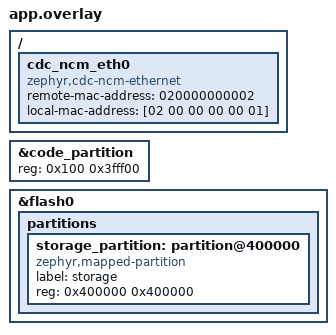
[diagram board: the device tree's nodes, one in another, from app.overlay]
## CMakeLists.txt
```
#pico-zephyr-project
#-------------------------------------------------------------------------------
# Zephyr Example Application
#
# Copyright (c) 2021 Nordic Semiconductor ASA
# SPDX-License-Identifier: Apache-2.0
#-------------------------------------------------------------------------------
# NOTE: Please do not remove the #pico-zephyr-project header, it is used by
# the Raspberry Pi Pico VS Code extension to identify the project type.
#-------------------------------------------------------------------------------

cmake_minimum_required(VERSION 3.20.0)

find_package(Zephyr REQUIRED HINTS $ENV{ZEPHYR_BASE})
project(pico_can_bridge LANGUAGES C)

target_sources(app PRIVATE
    src/can_bridge.c
    src/main.c
    src/http_server.c
    src/storage.c
    src/usb_descriptors.c
)
```

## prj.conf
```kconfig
# Logging
CONFIG_LOG=y
CONFIG_LOG_PRINTK=y
CONFIG_LOG_DEFAULT_LEVEL=3
CONFIG_USBD_LOG_LEVEL_INF=y
CONFIG_UDC_DRIVER_LOG_LEVEL_INF=y

# Board peripherals
CONFIG_GPIO=y
CONFIG_SPI=y
CONFIG_REBOOT=y
CONFIG_CAN=y
CONFIG_CAN_MCP2515=y
CONFIG_CAN_DEFAULT_BITRATE=500000
CONFIG_JSON_LIBRARY=y

# Experimental user storage. This branch mounts LittleFS lazily from HTTP
# handlers so boot and USB enumeration stay close to the stable firmware.
CONFIG_FLASH=y
CONFIG_FLASH_MAP=y
CONFIG_FILE_SYSTEM=y
CONFIG_FILE_SYSTEM_LITTLEFS=y
CONFIG_MAIN_STACK_SIZE=4096

# USB device stack next
CONFIG_USB_DEVICE_STACK_NEXT=y
CONFIG_CDC_ACM_SERIAL_INITIALIZE_AT_BOOT=n
CONFIG_USBD_CDC_NCM_LOG_LEVEL_INF=y

# Networking over USB CDC-NCM
CONFIG_NETWORKING=y
CONFIG_NET_L2_ETHERNET=y
CONFIG_NET_IPV4=y
CONFIG_NET_IPV4_AUTO=y
CONFIG_NET_ARP=y
CONFIG_NET_UDP=y
CONFIG_NET_TCP=y
CONFIG_NET_NATIVE=y
CONFIG_NET_MGMT=y
CONFIG_NET_MGMT_EVENT=y
CONFIG_NET_CONFIG_SETTINGS=n
CONFIG_NET_DHCPV4=n
CONFIG_NET_SOCKETS=y

# mDNS / DNS-SD
CONFIG_NET_HOSTNAME_ENABLE=y
CONFIG_NET_HOSTNAME_UNIQUE=n
CONFIG_NET_HOSTNAME="pico-can-bridge"
CONFIG_MDNS_RESPONDER=y
CONFIG_DNS_SD=y
CONFIG_MDNS_RESPONDER_DNS_SD=y
CONFIG_NET_IF_MCAST_IPV4_ADDR_COUNT=3

# Keep packet pools explicit for the RP2040's RAM budget.
CONFIG_ZVFS_POLL_MAX=9
CONFIG_NET_PKT_RX_COUNT=10
CONFIG_NET_PKT_TX_COUNT=10
CONFIG_NET_BUF_RX_COUNT=20
CONFIG_NET_BUF_TX_COUNT=20
CONFIG_NET_CONTEXT_NET_PKT_POOL=y
CONFIG_TEST_RANDOM_GENERATOR=y

CONFIG_SYSTEM_WORKQUEUE_STACK_SIZE=2048
```

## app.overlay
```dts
/*
 * USB CDC-NCM virtual Ethernet interface.
 *
 * The remote MAC is the address advertised for the host side of the link.
 */
/ {
	cdc_ncm_eth0: cdc_ncm_eth0 {
		compatible = "zephyr,cdc-ncm-ethernet";
		remote-mac-address = "020000000002";
		local-mac-address = [02 00 00 00 00 01];
	};
};

/*
 * Keep the last 4 MiB of the 8 MiB external flash for experimental LittleFS
 * user storage. The application stays in the first 4 MiB.
 */
&code_partition {
	reg = <0x100 0x3fff00>;
};

&flash0 {
	partitions {
		storage_partition: partition@400000 {
			compatible = "zephyr,mapped-partition";
			label = "storage";
			reg = <0x400000 0x400000>;
		};
	};
};
```

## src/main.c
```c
#include <zephyr/kernel.h>
#include <zephyr/logging/log.h>
#include <zephyr/drivers/gpio.h>
#include <zephyr/net/net_if.h>
#include <zephyr/net/net_ip.h>
#include <zephyr/net/net_mgmt.h>
#include <zephyr/usb/usbd.h>
#include <zephyr/usb/usbd_msg.h>
#include <zephyr/sys/reboot.h>

#include "can_bridge.h"

LOG_MODULE_REGISTER(main, CONFIG_LOG_DEFAULT_LEVEL);

#define LED0_NODE DT_ALIAS(led0)

enum status_led_mode {
	STATUS_LED_BLINK,
	STATUS_LED_SOLID,
	STATUS_LED_ERROR,
};

static const struct gpio_dt_spec led = GPIO_DT_SPEC_GET(LED0_NODE, gpios);
static atomic_t status_led_mode = ATOMIC_INIT(STATUS_LED_BLINK);
static atomic_t heartbeat_period_ms = ATOMIC_INIT(1000);
static atomic_t network_should_run;
static atomic_t network_is_up;
static atomic_t network_is_ready;
static atomic_t http_server_is_started;

struct usbd_context *usb_device_init(void);
int http_server_start(void);

static struct net_mgmt_event_callback ipv4_addr_cb;
static struct k_work_delayable usb_ncm_network_work;
static struct k_work_delayable usb_ncm_startup_watchdog_work;
static struct k_work http_server_start_work;

static void status_led_set_blink(int period_ms)
{
	atomic_set(&heartbeat_period_ms, period_ms);
	atomic_set(&status_led_mode, STATUS_LED_BLINK);
}

static void status_led_set_solid(void)
{
	atomic_set(&status_led_mode, STATUS_LED_SOLID);
}

static void status_led_set_error(void)
{
	atomic_set(&heartbeat_period_ms, 100);
	atomic_set(&status_led_mode, STATUS_LED_ERROR);
}

static void usb_ncm_network_work_handler(struct k_work *work)
{
	struct net_if *iface = net_if_get_default();
	bool should_run = atomic_get(&network_should_run) != 0;

	ARG_UNUSED(work);

	if (iface == NULL) {
		LOG_ERR("No default network interface");
		status_led_set_error();
		return;
	}

	if (should_run && !atomic_get(&network_is_up)) {
		net_if_up(iface);
		atomic_set(&network_is_up, 1);
		if (!atomic_get(&network_is_ready)) {
			LOG_INF("CDC-NCM waiting for IPv4 link-local autoconfiguration");
		}
		return;
	}

	if (!should_run && atomic_get(&network_is_up)) {
		net_if_down(iface);
		atomic_set(&network_is_up, 0);
		atomic_set(&network_is_ready, 0);
		status_led_set_blink(500);
		LOG_INF("CDC-NCM network interface down");
	}
}

static void set_usb_ncm_network_state(bool up)
{
	atomic_set(&network_should_run, up ? 1 : 0);

	if (up) {
		k_work_schedule(&usb_ncm_network_work, K_SECONDS(1));
	} else {
		(void)k_work_cancel_delayable(&usb_ncm_network_work);
		(void)k_work_cancel_delayable(&usb_ncm_startup_watchdog_work);
		k_work_schedule(&usb_ncm_network_work, K_NO_WAIT);
	}
}

static void usb_ncm_startup_watchdog_work_handler(struct k_work *work)
{
	ARG_UNUSED(work);

	if (!atomic_get(&network_should_run) || atomic_get(&network_is_ready)) {
		return;
	}

	LOG_ERR("CDC-NCM did not reach link-local state; rebooting for USB recovery");
	status_led_set_error();
	k_sleep(K_MSEC(250));
	sys_reboot(SYS_REBOOT_COLD);
}

static void http_server_start_work_handler(struct k_work *work)
{
	int ret;

	ARG_UNUSED(work);

	if (atomic_cas(&http_server_is_started, 0, 1) == false) {
		return;
	}

	ret = http_server_start();
	if (ret != 0) {
		LOG_ERR("HTTP server failed: %d", ret);
		atomic_set(&http_server_is_started, 0);
		status_led_set_error();
	}
}

static void usbd_msg_cb(struct usbd_context *const ctx,
			const struct usbd_msg *const msg)
{
	ARG_UNUSED(ctx);

	switch (msg->type) {
	case USBD_MSG_CONFIGURATION:
		LOG_INF("USBD message: %s", usbd_msg_type_string(msg->type));
		set_usb_ncm_network_state(true);
		k_work_reschedule(&usb_ncm_startup_watchdog_work, K_SECONDS(6));
		break;
	case USBD_MSG_STACK_ERROR:
	case USBD_MSG_UDC_ERROR:
		LOG_WRN("USBD message: %s", usbd_msg_type_string(msg->type));
		atomic_set(&network_is_ready, 0);
		status_led_set_blink(500);
		set_usb_ncm_network_state(false);
		break;
	case USBD_MSG_RESET:
	case USBD_MSG_SUSPEND:
	case USBD_MSG_VBUS_REMOVED:
		LOG_INF("USBD message: %s", usbd_msg_type_string(msg->type));
		atomic_set(&network_is_ready, 0);
		status_led_set_blink(500);
		set_usb_ncm_network_state(false);
		break;
	case USBD_MSG_RESUME:
	case USBD_MSG_VBUS_READY:
		LOG_INF("USBD message: %s", usbd_msg_type_string(msg->type));
		status_led_set_blink(500);
		set_usb_ncm_network_state(true);
		k_work_reschedule(&usb_ncm_startup_watchdog_work, K_SECONDS(6));
		break;
	default:
		LOG_DBG("USBD message: %s", usbd_msg_type_string(msg->type));
		break;
	}
}

static void heartbeat_thread(void)
{
	if (!gpio_is_ready_dt(&led)) {
		LOG_ERR("LED GPIO is not ready");
		return;
	}

	if (gpio_pin_configure_dt(&led, GPIO_OUTPUT_INACTIVE) < 0) {
		LOG_ERR("Failed to configure LED GPIO");
		return;
	}

	while (1) {
		switch (atomic_get(&status_led_mode)) {
		case STATUS_LED_SOLID:
			(void)gpio_pin_set_dt(&led, 1);
			k_sleep(K_SECONDS(1));
			break;
		case STATUS_LED_ERROR:
		case STATUS_LED_BLINK:
		default:
			(void)gpio_pin_toggle_dt(&led);
			k_sleep(K_MSEC(atomic_get(&heartbeat_period_ms)));
			break;
		}
	}
}

K_THREAD_DEFINE(heartbeat_tid, 512, heartbeat_thread, NULL, NULL, NULL,
		7, 0, 0);

static void ipv4_addr_handler(struct net_mgmt_event_callback *cb,
			      uint64_t mgmt_event,
			      struct net_if *iface)
{
	struct net_if_config *cfg = net_if_get_config(iface);

	ARG_UNUSED(cb);
	ARG_UNUSED(mgmt_event);

	if (cfg == NULL || cfg->ip.ipv4 == NULL) {
		return;
	}

	for (int i = 0; i < NET_IF_MAX_IPV4_ADDR; i++) {
		struct net_if_addr *ifaddr = &cfg->ip.ipv4->unicast[i].ipv4;
		char addr[NET_IPV4_ADDR_LEN];

		if (!ifaddr->is_used || ifaddr->addr_type != NET_ADDR_AUTOCONF) {
			continue;
		}

		LOG_INF("CDC-NCM link-local IPv4 address: %s",
			net_addr_ntop(AF_INET, &ifaddr->address.in_addr,
				      addr, sizeof(addr)));
		LOG_INF("mDNS hostname: %s.local", CONFIG_NET_HOSTNAME);
		LOG_INF("HTTP service: _http._tcp.local on port 80");

		atomic_set(&network_is_ready, 1);
		(void)k_work_cancel_delayable(&usb_ncm_startup_watchdog_work);
		status_led_set_solid();
		k_work_submit(&http_server_start_work);
	}
}

static void register_usb_ncm_network_callbacks(void)
{
	k_work_init_delayable(&usb_ncm_network_work, usb_ncm_network_work_handler);
	k_work_init_delayable(&usb_ncm_startup_watchdog_work,
			      usb_ncm_startup_watchdog_work_handler);
	k_work_init(&http_server_start_work, http_server_start_work_handler);

	net_mgmt_init_event_callback(&ipv4_addr_cb, ipv4_addr_handler,
				     NET_EVENT_IPV4_ADDR_ADD);
	net_mgmt_add_event_callback(&ipv4_addr_cb);
}

int main(void)
{
	struct usbd_context *usbd;
	int ret;

	printk("Pico CAN Bridge CDC-NCM firmware\n");
	LOG_INF("Booted on %s", CONFIG_BOARD_TARGET);

	usbd = usb_device_init();
	if (usbd == NULL) {
		LOG_ERR("USB init failed");
		status_led_set_error();
		return 0;
	}

	register_usb_ncm_network_callbacks();

	ret = usbd_msg_register_cb(usbd, usbd_msg_cb);
	if (ret != 0) {
		LOG_ERR("USB message callback registration failed: %d", ret);
		status_led_set_error();
		return 0;
	}

	ret = usbd_enable(usbd);
	if (ret != 0) {
		LOG_ERR("USB enable failed: %d", ret);
		status_led_set_error();
		return 0;
	}

	status_led_set_blink(500);
	LOG_INF("USB CDC-NCM enabled");

	ret = can_bridge_init();
	if (ret != 0) {
		LOG_WRN("CAN bridge init failed: %d", ret);
	}

	while (1) {
		k_sleep(K_SECONDS(10));
	}

	return 0;
}
```

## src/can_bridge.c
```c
#include "can_bridge.h"

#include <errno.h>
#include <stdbool.h>
#include <stdint.h>
#include <string.h>

#include <zephyr/data/json.h>
#include <zephyr/device.h>
#include <zephyr/devicetree.h>
#include <zephyr/drivers/can.h>
#include <zephyr/kernel.h>
#include <zephyr/logging/log.h>
#include <zephyr/sys/util.h>

LOG_MODULE_REGISTER(can_bridge, CONFIG_LOG_DEFAULT_LEVEL);

#define CAN_NODE DT_CHOSEN(zephyr_canbus)
#define CAN_TX_TIMEOUT K_MSEC(100)
#define CAN_WS_JSON_MAX 256
#define CAN_TX_QUEUE_LEN 8
#define CAN_RX_QUEUE_LEN 8
#define CAN_TX_STACK_SIZE 2048
#define CAN_TX_PRIORITY 8

enum can_json_field {
	CAN_JSON_TYPE,
	CAN_JSON_BUS,
	CAN_JSON_ID,
	CAN_JSON_EXT,
	CAN_JSON_RTR,
	CAN_JSON_DLC,
	CAN_JSON_DATA,
	CAN_JSON_BITRATE,
	CAN_JSON_MODE,
};

struct can_json_message {
	const char *type;
	int32_t bus;
	int32_t id;
	bool ext;
	bool rtr;
	int32_t dlc;
	int32_t data[CAN_MAX_DLC];
	size_t data_len;
	int32_t bitrate;
	const char *mode;
};

static const struct device *const can_dev = DEVICE_DT_GET(CAN_NODE);
static atomic_t can_ready;
static uint32_t current_bitrate = CONFIG_CAN_DEFAULT_BITRATE;
static can_mode_t current_mode = CAN_MODE_NORMAL;
K_MSGQ_DEFINE(can_tx_queue, sizeof(struct can_frame),
	      CAN_TX_QUEUE_LEN, sizeof(uint32_t));
K_MSGQ_DEFINE(can_rx_queue, sizeof(struct can_frame),
	      CAN_RX_QUEUE_LEN, sizeof(uint32_t));
static K_THREAD_STACK_DEFINE(can_tx_stack, CAN_TX_STACK_SIZE);
static struct k_thread can_tx_thread_data;
static K_MUTEX_DEFINE(can_lock);
static int can_rx_filter_id = -1;
static atomic_t can_rx_streaming;

static const struct json_obj_descr can_json_descr[] = {
	JSON_OBJ_DESCR_PRIM(struct can_json_message, type, JSON_TOK_STRING),
	JSON_OBJ_DESCR_PRIM(struct can_json_message, bus, JSON_TOK_NUMBER),
	JSON_OBJ_DESCR_PRIM(struct can_json_message, id, JSON_TOK_NUMBER),
	JSON_OBJ_DESCR_PRIM(struct can_json_message, ext, JSON_TOK_TRUE),
	JSON_OBJ_DESCR_PRIM(struct can_json_message, rtr, JSON_TOK_TRUE),
	JSON_OBJ_DESCR_PRIM(struct can_json_message, dlc, JSON_TOK_NUMBER),
	JSON_OBJ_DESCR_ARRAY(struct can_json_message, data, CAN_MAX_DLC,
			     data_len, JSON_TOK_NUMBER),
	JSON_OBJ_DESCR_PRIM(struct can_json_message, bitrate, JSON_TOK_NUMBER),
	JSON_OBJ_DESCR_PRIM(struct can_json_message, mode, JSON_TOK_STRING),
};

static int ws_reply(char *response, size_t response_len, const char *code,
		    const char *message, int err)
{
	return snprintk(response, response_len,
			"{\"type\":\"error\",\"ok\":false,\"code\":\"%s\","
			"\"err\":%d,\"message\":\"%s\"}",
			code, err, message);
}

static const char *can_state_name(enum can_state state)
{
	switch (state) {
	case CAN_STATE_ERROR_ACTIVE:
		return "error-active";
	case CAN_STATE_ERROR_WARNING:
		return "error-warning";
	case CAN_STATE_ERROR_PASSIVE:
		return "error-passive";
	case CAN_STATE_BUS_OFF:
		return "bus-off";
	case CAN_STATE_STOPPED:
		return "stopped";
	default:
		return "unknown";
	}
}

static const char *can_mode_name(can_mode_t mode)
{
	if ((mode & CAN_MODE_LOOPBACK) != 0) {
		return "loopback";
	}

	if ((mode & CAN_MODE_LISTENONLY) != 0) {
		return "listen-only";
	}

	return "normal";
}

static int can_mode_from_name(const char *name, can_mode_t *mode)
{
	if (name == NULL || strcmp(name, "normal") == 0) {
		*mode = CAN_MODE_NORMAL;
		return 0;
	}

	if (strcmp(name, "loopback") == 0) {
		*mode = CAN_MODE_LOOPBACK;
		return 0;
	}

	if (strcmp(name, "listen-only") == 0) {
		*mode = CAN_MODE_LISTENONLY;
		return 0;
	}

	return -EINVAL;
}

int can_bridge_format_status(char *response, size_t response_len)
{
	struct can_bus_err_cnt err_cnt = { 0 };
	enum can_state state = CAN_STATE_STOPPED;
	int ret;

	k_mutex_lock(&can_lock, K_FOREVER);
	ret = can_get_state(can_dev, &state, &err_cnt);
	k_mutex_unlock(&can_lock);
	if (ret < 0) {
		return ws_reply(response, response_len, "can_status_failed",
				"Could not read CAN controller status", ret);
	}

	return snprintk(response, response_len,
			"{\"type\":\"can.status\",\"ok\":true,\"bus\":0,"
			"\"ready\":%s,\"state\":\"%s\",\"bitrate\":%u,"
			"\"mode\":\"%s\",\"txErr\":%u,\"rxErr\":%u,"
			"\"txQueueUsed\":%u,\"txQueueFree\":%u,"
			"\"rxQueueUsed\":%u,\"rxQueueFree\":%u}",
			atomic_get(&can_ready) ? "true" : "false",
			can_state_name(state), current_bitrate,
			can_mode_name(current_mode), err_cnt.tx_err_cnt,
			err_cnt.rx_err_cnt,
			k_msgq_num_used_get(&can_tx_queue),
			k_msgq_num_free_get(&can_tx_queue),
			k_msgq_num_used_get(&can_rx_queue),
			k_msgq_num_free_get(&can_rx_queue));
}

static void can_rx_callback(const struct device *dev, struct can_frame *frame,
			    void *user_data)
{
	ARG_UNUSED(dev);
	ARG_UNUSED(user_data);

	if (!atomic_get(&can_rx_streaming)) {
		return;
	}

	if (k_msgq_put(&can_rx_queue, frame, K_NO_WAIT) != 0) {
		LOG_WRN("CAN RX software queue full");
	}
}

void can_bridge_set_rx_streaming(bool enabled)
{
	if (enabled) {
		k_msgq_purge(&can_rx_queue);
		atomic_set(&can_rx_streaming, 1);
		return;
	}

	atomic_clear(&can_rx_streaming);
	k_msgq_purge(&can_rx_queue);
}

static void can_tx_thread(void *p1, void *p2, void *p3)
{
	ARG_UNUSED(p1);
	ARG_UNUSED(p2);
	ARG_UNUSED(p3);

	while (1) {
		struct can_frame frame;
		int ret;

		k_msgq_get(&can_tx_queue, &frame, K_FOREVER);

		LOG_INF("CAN TX worker sending: id=%u ext=%d rtr=%d dlc=%d",
			frame.id, (frame.flags & CAN_FRAME_IDE) != 0,
			(frame.flags & CAN_FRAME_RTR) != 0, frame.dlc);

		k_mutex_lock(&can_lock, K_FOREVER);
		ret = can_send(can_dev, &frame, CAN_TX_TIMEOUT, NULL, NULL);
		k_mutex_unlock(&can_lock);
		if (ret < 0) {
			LOG_WRN("CAN TX failed: %d", ret);
			continue;
		}

		LOG_INF("CAN TX submitted");
	}
}

int can_bridge_init(void)
{
	int ret;

	if (!device_is_ready(can_dev)) {
		LOG_ERR("CAN device is not ready");
		return -ENODEV;
	}

	ret = can_set_mode(can_dev, current_mode);
	if (ret < 0) {
		LOG_ERR("CAN normal mode failed: %d", ret);
		return ret;
	}

	ret = can_start(can_dev);
	if (ret < 0 && ret != -EALREADY) {
		LOG_ERR("CAN start failed: %d", ret);
		return ret;
	}

	const struct can_filter catch_all = {
		.id = 0,
		.mask = 0,
		.flags = 0,
	};

	can_rx_filter_id = can_add_rx_filter(can_dev, can_rx_callback, NULL,
					     &catch_all);
	if (can_rx_filter_id < 0) {
		LOG_ERR("CAN RX filter failed: %d", can_rx_filter_id);
		return can_rx_filter_id;
	}

	atomic_set(&can_ready, 1);
	k_thread_create(&can_tx_thread_data, can_tx_stack,
			K_THREAD_STACK_SIZEOF(can_tx_stack),
			can_tx_thread, NULL, NULL, NULL,
			CAN_TX_PRIORITY, 0, K_NO_WAIT);
	LOG_INF("CAN bus ready in normal mode at %u bit/s",
		CONFIG_CAN_DEFAULT_BITRATE);
	return 0;
}

int can_bridge_format_next_rx(char *response, size_t response_len)
{
	struct can_frame frame;
	size_t offset = 0;
	int ret;

	ret = k_msgq_get(&can_rx_queue, &frame, K_NO_WAIT);
	if (ret != 0) {
		return -EAGAIN;
	}

	ret = snprintk(response, response_len,
		       "{\"type\":\"can.rx\",\"bus\":0,\"id\":%u,"
		       "\"ext\":%s,\"rtr\":%s,\"dlc\":%u,\"data\":[",
		       frame.id,
		       (frame.flags & CAN_FRAME_IDE) != 0 ? "true" : "false",
		       (frame.flags & CAN_FRAME_RTR) != 0 ? "true" : "false",
		       frame.dlc);
	if (ret < 0 || ret >= response_len) {
		return -ENOMEM;
	}

	offset = ret;
	for (uint8_t i = 0; i < frame.dlc; i++) {
		ret = snprintk(&response[offset], response_len - offset,
			       "%s%u", i == 0 ? "" : ",", frame.data[i]);
		if (ret < 0 || ret >= response_len - offset) {
			return -ENOMEM;
		}
		offset += ret;
	}

	ret = snprintk(&response[offset], response_len - offset,
		       "],\"ts\":%lld}",
		       (long long)k_ticks_to_us_floor64(k_uptime_ticks()));
	if (ret < 0 || ret >= response_len - offset) {
		return -ENOMEM;
	}

	return 0;
}

static int format_can_tx_response(const struct can_json_message *msg,
				  char *response, size_t response_len)
{
	size_t offset;
	int ret;

	ret = snprintk(response, response_len,
		       "{\"type\":\"can.tx\",\"ok\":true,\"bus\":%d,"
		       "\"id\":%d,\"ext\":%s,\"rtr\":%s,\"dlc\":%d,"
		       "\"data\":[",
		       msg->bus, msg->id, msg->ext ? "true" : "false",
		       msg->rtr ? "true" : "false", msg->dlc);
	if (ret < 0 || ret >= response_len) {
		return -ENOMEM;
	}

	offset = ret;
	for (size_t i = 0; i < msg->data_len; i++) {
		ret = snprintk(&response[offset], response_len - offset,
			       "%s%d", i == 0 ? "" : ",", msg->data[i]);
		if (ret < 0 || ret >= response_len - offset) {
			return -ENOMEM;
		}
		offset += ret;
	}

	ret = snprintk(&response[offset], response_len - offset,
		       "],\"queued\":true,\"ts\":%lld}",
		       (long long)k_ticks_to_us_floor64(k_uptime_ticks()));
	if (ret < 0 || ret >= response_len - offset) {
		return -ENOMEM;
	}

	return 0;
}

static int validate_can_json(const struct can_json_message *msg, int64_t fields,
			     char *response, size_t response_len)
{
	const int64_t required = BIT(CAN_JSON_BUS) | BIT(CAN_JSON_ID) |
				 BIT(CAN_JSON_DLC);
	bool has_data = (fields & BIT(CAN_JSON_DATA)) != 0;

	if ((fields & required) != required) {
		return ws_reply(response, response_len, "missing_field",
				"CAN JSON must include bus, id and dlc", -EINVAL);
	}

	if (msg->bus != 0) {
		return ws_reply(response, response_len, "unsupported_bus",
				"Only CAN bus 0 is available", -ENODEV);
	}

	if (msg->dlc < 0 || msg->dlc > CAN_MAX_DLC) {
		return ws_reply(response, response_len, "invalid_dlc",
				"CAN dlc must be between 0 and 8", -EINVAL);
	}

	if (msg->id < 0 ||
	    (!msg->ext && msg->id > CAN_STD_ID_MASK) ||
	    (msg->ext && msg->id > CAN_EXT_ID_MASK)) {
		return ws_reply(response, response_len, "invalid_id",
				"CAN id is outside the selected frame format",
				-EINVAL);
	}

	if (!msg->rtr && msg->dlc > 0 && !has_data) {
		return ws_reply(response, response_len, "missing_data",
				"Data frames with dlc > 0 must include data",
				-EINVAL);
	}

	if (!msg->rtr && msg->data_len != (size_t)msg->dlc) {
		return ws_reply(response, response_len, "data_length_mismatch",
				"data length must match dlc", -EINVAL);
	}

	if (msg->rtr && has_data && msg->data_len > 0) {
		return ws_reply(response, response_len, "rtr_has_data",
				"RTR frames must not include data bytes", -EINVAL);
	}

	for (size_t i = 0; i < msg->data_len; i++) {
		if (msg->data[i] < 0 || msg->data[i] > 0xff) {
			return ws_reply(response, response_len, "invalid_data",
					"CAN data bytes must be between 0 and 255",
					-EINVAL);
		}
	}

	return 0;
}

static int handle_can_config_set(const struct can_json_message *msg,
				 int64_t fields, char *response,
				 size_t response_len)
{
	uint32_t bitrate = current_bitrate;
	can_mode_t mode = current_mode;
	int ret;

	if ((fields & BIT(CAN_JSON_BITRATE)) != 0) {
		if (msg->bitrate <= 0) {
			return ws_reply(response, response_len, "invalid_bitrate",
					"CAN bitrate must be positive", -EINVAL);
		}

		bitrate = (uint32_t)msg->bitrate;
	}

	if ((fields & BIT(CAN_JSON_MODE)) != 0) {
		ret = can_mode_from_name(msg->mode, &mode);
		if (ret < 0) {
			return ws_reply(response, response_len, "invalid_mode",
					"CAN mode must be normal, loopback or listen-only",
					ret);
		}
	}

	atomic_clear(&can_ready);
	k_mutex_lock(&can_lock, K_FOREVER);

	ret = can_stop(can_dev);
	if (ret < 0 && ret != -EALREADY) {
		goto out;
	}

	ret = can_set_mode(can_dev, mode);
	if (ret < 0) {
		goto out;
	}

	ret = can_set_bitrate(can_dev, bitrate);
	if (ret < 0) {
		goto out;
	}

	ret = can_start(can_dev);
	if (ret < 0 && ret != -EALREADY) {
		goto out;
	}

	current_mode = mode;
	current_bitrate = bitrate;
	atomic_set(&can_ready, 1);

out:
	k_mutex_unlock(&can_lock);
	if (ret < 0) {
		int config_ret = ret;

		k_mutex_lock(&can_lock, K_FOREVER);
		ret = can_start(can_dev);
		if (ret == 0 || ret == -EALREADY) {
			atomic_set(&can_ready, 1);
		}
		k_mutex_unlock(&can_lock);
		return ws_reply(response, response_len, "can_config_failed",
				"Could not apply CAN configuration", config_ret);
	}

	LOG_INF("CAN config applied: bitrate=%u mode=%s",
		current_bitrate, can_mode_name(current_mode));
	return can_bridge_format_status(response, response_len);
}

int can_bridge_handle_ws_text(const uint8_t *payload, size_t payload_len,
			      char *response, size_t response_len)
{
	struct can_json_message msg = { 0 };
	struct can_frame frame = { 0 };
	char json[CAN_WS_JSON_MAX];
	int64_t fields;
	int ret;

	if (!atomic_get(&can_ready)) {
		return ws_reply(response, response_len, "can_not_ready",
				"CAN controller is not ready", -ENODEV);
	}

	if (payload_len >= sizeof(json)) {
		return ws_reply(response, response_len, "payload_too_large",
				"WebSocket JSON payload is too large", -EMSGSIZE);
	}

	memcpy(json, payload, payload_len);
	json[payload_len] = '\0';

	fields = json_obj_parse(json, payload_len, can_json_descr,
				ARRAY_SIZE(can_json_descr), &msg);
	if (fields < 0) {
		return ws_reply(response, response_len, "invalid_json",
				"Could not parse CAN JSON payload", (int)fields);
	}

	if ((fields & BIT(CAN_JSON_TYPE)) != 0) {
		if (strcmp(msg.type, "can.status") == 0 ||
		    strcmp(msg.type, "can.config.get") == 0) {
			return can_bridge_format_status(response, response_len);
		}

		if (strcmp(msg.type, "can.config.set") == 0) {
			return handle_can_config_set(&msg, fields, response,
						     response_len);
		}

		if (strcmp(msg.type, "can.tx") != 0) {
			return ws_reply(response, response_len, "unsupported_type",
					"Unsupported WebSocket message type",
					-ENOTSUP);
		}
	}

	ret = validate_can_json(&msg, fields, response, response_len);
	if (ret != 0) {
		return ret;
	}

	frame.id = (uint32_t)msg.id;
	frame.dlc = (uint8_t)msg.dlc;
	frame.flags = (msg.ext ? CAN_FRAME_IDE : 0) |
		      (msg.rtr ? CAN_FRAME_RTR : 0);

	for (size_t i = 0; i < msg.data_len; i++) {
		frame.data[i] = (uint8_t)msg.data[i];
	}

	LOG_INF("CAN TX request accepted: bus=%d id=%d ext=%d rtr=%d dlc=%d",
		msg.bus, msg.id, msg.ext, msg.rtr, msg.dlc);

	ret = k_msgq_put(&can_tx_queue, &frame, K_NO_WAIT);
	if (ret < 0) {
		LOG_WRN("CAN TX software queue full: %d", ret);
		(void)ws_reply(response, response_len, "can_tx_failed",
			       "CAN TX software queue is full", ret);
		return ret;
	}

	return format_can_tx_response(&msg, response, response_len);
}
```

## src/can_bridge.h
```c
#ifndef CAN_BRIDGE_H
#define CAN_BRIDGE_H

#include <stddef.h>
#include <stdbool.h>
#include <stdint.h>

int can_bridge_init(void);
int can_bridge_handle_ws_text(const uint8_t *payload, size_t payload_len,
			      char *response, size_t response_len);
int can_bridge_format_next_rx(char *response, size_t response_len);
int can_bridge_format_status(char *response, size_t response_len);
void can_bridge_set_rx_streaming(bool enabled);

#endif
```

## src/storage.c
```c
#include "storage.h"

#include <errno.h>
#include <stdbool.h>
#include <stdint.h>

#include <zephyr/fs/fs.h>
#include <zephyr/fs/littlefs.h>
#include <zephyr/kernel.h>
#include <zephyr/logging/log.h>
#include <zephyr/storage/flash_map.h>
#include <zephyr/sys/util.h>

LOG_MODULE_REGISTER(storage, CONFIG_LOG_DEFAULT_LEVEL);

#define STORAGE_PATH "/lfs"
#define USER_DIR_PATH STORAGE_PATH "/user"
#define USER_INDEX_PATH STORAGE_PATH "/user/index.html"
#define STORAGE_PARTITION storage_partition
#define STORAGE_IO_CHUNK 512

FS_LITTLEFS_DECLARE_DEFAULT_CONFIG(storage);

static struct fs_mount_t storage_mount = {
	.type = FS_LITTLEFS,
	.fs_data = &storage,
	.storage_dev = (void *)PARTITION_ID(STORAGE_PARTITION),
	.mnt_point = STORAGE_PATH,
};

static K_MUTEX_DEFINE(storage_lock);
static bool mount_attempted;
static bool mounted;
static int mount_ret = -ENODEV;
static unsigned long total_kib;
static unsigned long free_kib;

static void update_space_locked(void)
{
	struct fs_statvfs stat;
	int ret;

	total_kib = 0;
	free_kib = 0;

	if (!mounted) {
		return;
	}

	ret = fs_statvfs(STORAGE_PATH, &stat);
	if (ret < 0) {
		LOG_WRN("LittleFS statvfs failed: %d", ret);
		return;
	}

	total_kib = (unsigned long)((uint64_t)stat.f_frsize * stat.f_blocks / 1024U);
	free_kib = (unsigned long)((uint64_t)stat.f_frsize * stat.f_bfree / 1024U);
}

int storage_mount_once(void)
{
	int ret;

	k_mutex_lock(&storage_lock, K_FOREVER);
	if (mount_attempted) {
		ret = mount_ret;
		k_mutex_unlock(&storage_lock);
		return ret;
	}

	mount_attempted = true;
	ret = fs_mount(&storage_mount);
	mount_ret = ret;
	mounted = (ret == 0);

	if (ret == 0) {
		update_space_locked();
		LOG_INF("LittleFS mounted at %s: %lu KiB total, %lu KiB free",
			STORAGE_PATH, total_kib, free_kib);
	} else {
		LOG_WRN("LittleFS mount failed: %d", ret);
	}

	k_mutex_unlock(&storage_lock);
	return ret;
}

void storage_get_status(struct storage_status *status)
{
	k_mutex_lock(&storage_lock, K_FOREVER);
	update_space_locked();
	status->attempted = mount_attempted;
	status->mounted = mounted;
	status->mount_ret = mount_ret;
	status->total_kib = total_kib;
	status->free_kib = free_kib;
	k_mutex_unlock(&storage_lock);
}

int storage_format_status_json(char *response, size_t response_len)
{
	struct storage_status status;

	(void)storage_mount_once();
	storage_get_status(&status);

	return snprintk(response, response_len,
			"{\"type\":\"fs.status\",\"ok\":%s,"
			"\"attempted\":%s,\"mounted\":%s,"
			"\"mountRet\":%d,\"path\":\"%s\","
			"\"totalKiB\":%lu,\"freeKiB\":%lu}",
			status.mounted ? "true" : "false",
			status.attempted ? "true" : "false",
			status.mounted ? "true" : "false",
			status.mount_ret, STORAGE_PATH,
			status.total_kib, status.free_kib);
}

int storage_user_index_size(size_t *len)
{
	struct fs_dirent entry;
	int ret;

	if (len == NULL) {
		return -EINVAL;
	}

	ret = storage_mount_once();
	if (ret < 0) {
		return ret;
	}

	ret = fs_stat(USER_INDEX_PATH, &entry);
	if (ret < 0) {
		return ret;
	}

	if (entry.type != FS_DIR_ENTRY_FILE) {
		return -EISDIR;
	}

	*len = entry.size;
	return 0;
}

int storage_stream_user_index(storage_write_cb_t writer, void *ctx)
{
	struct fs_file_t file;
	uint8_t buf[STORAGE_IO_CHUNK];
	int ret;

	if (writer == NULL) {
		return -EINVAL;
	}

	ret = storage_mount_once();
	if (ret < 0) {
		return ret;
	}

	fs_file_t_init(&file);
	ret = fs_open(&file, USER_INDEX_PATH, FS_O_READ);
	if (ret < 0) {
		return ret;
	}

	while (1) {
		ssize_t read_len = fs_read(&file, buf, sizeof(buf));

		if (read_len < 0) {
			ret = (int)read_len;
			break;
		}

		if (read_len == 0) {
			ret = 0;
			break;
		}

		ret = writer(ctx, buf, (size_t)read_len);
		if (ret < 0) {
			break;
		}
	}

	(void)fs_close(&file);
	return ret;
}

int storage_write_user_index_stream(size_t len, storage_read_cb_t reader,
				    void *ctx)
{
	struct fs_file_t file;
	struct fs_dirent entry;
	uint8_t buf[STORAGE_IO_CHUNK];
	size_t remaining = len;
	int ret;

	if (reader == NULL) {
		return -EINVAL;
	}

	ret = storage_mount_once();
	if (ret < 0) {
		return ret;
	}

	ret = fs_stat(USER_DIR_PATH, &entry);
	if (ret == -ENOENT) {
		ret = fs_mkdir(USER_DIR_PATH);
		if (ret < 0) {
			return ret;
		}
	} else if (ret < 0) {
		return ret;
	} else if (entry.type != FS_DIR_ENTRY_DIR) {
		return -ENOTDIR;
	}

	fs_file_t_init(&file);
	ret = fs_open(&file, USER_INDEX_PATH,
		      FS_O_CREATE | FS_O_TRUNC | FS_O_WRITE);
	if (ret < 0) {
		return ret;
	}

	while (remaining > 0) {
		size_t requested = MIN(remaining, sizeof(buf));
		size_t read_len = 0;
		size_t written_total = 0;

		ret = reader(ctx, buf, requested, &read_len);
		if (ret < 0) {
			break;
		}

		if (read_len == 0 || read_len > requested) {
			ret = -EIO;
			break;
		}

		while (written_total < read_len) {
			ssize_t written = fs_write(&file,
						   &buf[written_total],
						   read_len - written_total);
			if (written < 0) {
				ret = (int)written;
				break;
			}

			if (written == 0) {
				ret = -EIO;
				break;
			}

			written_total += (size_t)written;
		}

		if (ret < 0) {
			break;
		}

		remaining -= read_len;
	}

	if (ret < 0) {
		(void)fs_close(&file);
		return ret;
	}

	ret = fs_sync(&file);
	(void)fs_close(&file);

	if (ret < 0) {
		return ret;
	}

	if (remaining != 0) {
		return -EIO;
	}

	k_mutex_lock(&storage_lock, K_FOREVER);
	update_space_locked();
	k_mutex_unlock(&storage_lock);

	LOG_INF("Wrote %u bytes to %s", (unsigned int)len, USER_INDEX_PATH);
	return 0;
}
```

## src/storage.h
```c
#ifndef STORAGE_H
#define STORAGE_H

#include <stdbool.h>
#include <stddef.h>
#include <stdint.h>

struct storage_status {
	bool attempted;
	bool mounted;
	int mount_ret;
	unsigned long total_kib;
	unsigned long free_kib;
};

typedef int (*storage_read_cb_t)(void *ctx, uint8_t *buf, size_t max_len,
				 size_t *len);
typedef int (*storage_write_cb_t)(void *ctx, const uint8_t *buf, size_t len);

int storage_mount_once(void);
void storage_get_status(struct storage_status *status);
int storage_format_status_json(char *response, size_t response_len);
int storage_user_index_size(size_t *len);
int storage_stream_user_index(storage_write_cb_t writer, void *ctx);
int storage_write_user_index_stream(size_t len, storage_read_cb_t reader,
				    void *ctx);

#endif
```

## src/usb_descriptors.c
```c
#include <zephyr/device.h>
#include <zephyr/usb/usbd.h>
#include <zephyr/usb/usb_ch9.h>

#include <zephyr/logging/log.h>
LOG_MODULE_REGISTER(usb_descriptors, CONFIG_LOG_DEFAULT_LEVEL);

#define USB_VID_ZEPHYR 0x2FE3
#define USB_PID_PICO_CAN_BRIDGE 0x0100

USBD_DEVICE_DEFINE(pico_can_bridge_usbd,
		   DEVICE_DT_GET(DT_NODELABEL(zephyr_udc0)),
		   USB_VID_ZEPHYR, USB_PID_PICO_CAN_BRIDGE);

USBD_DESC_LANG_DEFINE(lang_desc);
USBD_DESC_MANUFACTURER_DEFINE(mfr_desc, "pico-can-bridge");
USBD_DESC_PRODUCT_DEFINE(product_desc, "Pico CAN Bridge CDC-NCM");
USBD_DESC_SERIAL_NUMBER_DEFINE(serial_desc);

USBD_DESC_CONFIG_DEFINE(fs_cfg_desc, "CDC-NCM");

USBD_CONFIGURATION_DEFINE(fs_config,
			  USB_SCD_SELF_POWERED,
			  100,
			  &fs_cfg_desc);

struct usbd_context *usb_device_init(void)
{
	int err;

	err = usbd_add_descriptor(&pico_can_bridge_usbd, &lang_desc);
	if (err) {
		LOG_ERR("language descriptor failed: %d", err);
		return NULL;
	}

	err = usbd_add_descriptor(&pico_can_bridge_usbd, &mfr_desc);
	if (err) {
		LOG_ERR("manufacturer descriptor failed: %d", err);
		return NULL;
	}

	err = usbd_add_descriptor(&pico_can_bridge_usbd, &product_desc);
	if (err) {
		LOG_ERR("product descriptor failed: %d", err);
		return NULL;
	}

	err = usbd_add_descriptor(&pico_can_bridge_usbd, &serial_desc);
	if (err) {
		LOG_ERR("serial descriptor failed: %d", err);
		return NULL;
	}

	err = usbd_add_configuration(&pico_can_bridge_usbd,
				     USBD_SPEED_FS,
				     &fs_config);
	if (err) {
		LOG_ERR("FS configuration failed: %d", err);
		return NULL;
	}

	err = usbd_register_all_classes(&pico_can_bridge_usbd,
					USBD_SPEED_FS,
					1,
					NULL);
	if (err) {
		LOG_ERR("class registration failed: %d", err);
		return NULL;
	}

	usbd_device_set_code_triple(&pico_can_bridge_usbd,
				    USBD_SPEED_FS,
				    USB_BCC_MISCELLANEOUS,
				    0x02,
				    0x01);
	usbd_self_powered(&pico_can_bridge_usbd, true);

	err = usbd_init(&pico_can_bridge_usbd);
	if (err) {
		LOG_ERR("USB device init failed: %d", err);
		return NULL;
	}

	return &pico_can_bridge_usbd;
}
```
